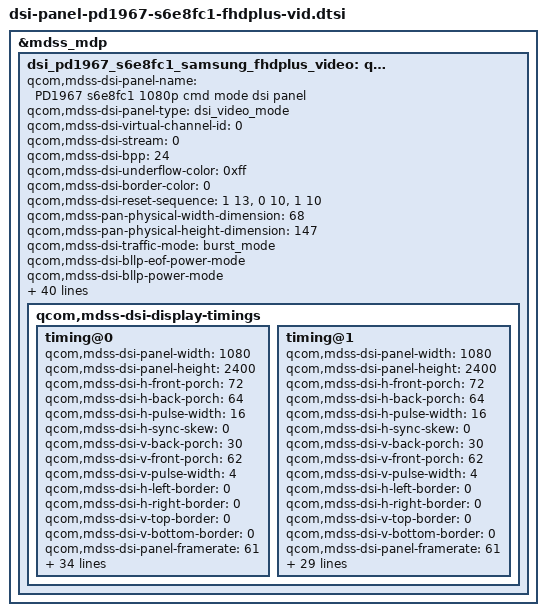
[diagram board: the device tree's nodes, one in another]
/* Copyright (c) 2019, The Linux Foundation. All rights reserved.
 *
 * This program is free software; you can redistribute it and/or modify
 * it under the terms of the GNU General Public License version 2 and
 * only version 2 as published by the Free Software Foundation.
 *
 * This program is distributed in the hope that it will be useful,
 * but WITHOUT ANY WARRANTY; without even the implied warranty of
 * MERCHANTABILITY or FITNESS FOR A PARTICULAR PURPOSE.  See the
 * GNU General Public License for more details.
 */

&mdss_mdp {
	dsi_pd1967_s6e8fc1_samsung_fhdplus_video: qcom,PD1967_mdss_dsi_s6e8fc1_fhdplus_cmd {
		qcom,mdss-dsi-panel-name = "PD1967 s6e8fc1 1080p cmd mode dsi panel";
		qcom,mdss-dsi-panel-type = "dsi_video_mode";
		qcom,mdss-dsi-virtual-channel-id = <0>;
		qcom,mdss-dsi-stream = <0>;
		qcom,mdss-dsi-bpp = <24>;
		qcom,mdss-dsi-underflow-color = <0xff>;
		qcom,mdss-dsi-border-color = <0>;
		qcom,mdss-dsi-reset-sequence = <1 13>, <0 10>, <1 10>;
		qcom,mdss-pan-physical-width-dimension = <68>;
		qcom,mdss-pan-physical-height-dimension = <147>;
		qcom,mdss-dsi-traffic-mode = "burst_mode";//"non_burst_sync_event";
		qcom,mdss-dsi-bllp-eof-power-mode;
		qcom,mdss-dsi-bllp-power-mode;
		qcom,mdss-dsi-lane-0-state;
		qcom,mdss-dsi-lane-1-state;
		qcom,mdss-dsi-lane-2-state;
		qcom,mdss-dsi-lane-3-state;
		qcom,mdss-dsi-dma-trigger = "trigger_sw";
		qcom,mdss-dsi-mdp-trigger = "none";
		qcom,mdss-dsi-lp11-init;
		qcom,mdss-dsi-panel-id = <0x21>;
		qcom,mdss-dsi-project-name = "pd1982";
		qcom,vivo-dsi-panel-type = "oled";
		qcom,dsi-dyn-clk-enable;
		qcom,dsi-dyn-clk-list = <1125476352 1115097984>;
		qcom,mdss-dsi-te-pin-select = <1>;
		qcom,mdss-dsi-wr-mem-start = <0x2c>;
		qcom,mdss-dsi-wr-mem-continue = <0x3c>;
		qcom,mdss-dsi-te-dcs-command = <1>;
		qcom,mdss-dsi-te-check-enable;
		qcom,mdss-dsi-te-using-te-pin;
		qcom,mdss-dsi-panel-mode-switch;

		//qcom,esd-check-enabled;
		qcom,mdss-dsi-panel-status-check-mode = "reg_read";
		qcom,mdss-dsi-panel-status-command = [06 01 00 01 00 00 01 0a];
		qcom,mdss-dsi-panel-status-command-state = "dsi_lp_mode";
		qcom,mdss-dsi-panel-status-value = <0x9F>;
		qcom,mdss-dsi-panel-on-check-value = <0x9F>;
		qcom,mdss-dsi-panel-status-read-length = <1>;
		qcom,mdss-dsi-t-clk-post = <0x0F>;

		qcom,mdss-dsi-t-clk-pre = <0x3A>;

		qcom,panel-supply-entries = <&dsi_panel_pwr_supply_no_labibb>;
		qcom,mdss-dsi-bl-pmic-control-type = "bl_ctrl_dcs";
		qcom,mdss-dsi-bl-min-level = <1>;
		qcom,mdss-dsi-bl-max-level = <2047>;
		qcom,mdss-brightness-max-level = <2047>;
		qcom,platform-en-gpio = <&tlmm 129 0>;
		qcom,platform-te-gpio = <&tlmm 89 0>;
		qcom,platform-reset-gpio = <&tlmm 90 0>;
		

		qcom,mdss-dsi-display-timings {
			timing@0{
				qcom,mdss-dsi-panel-width = <1080>;
				qcom,mdss-dsi-panel-height = <2400>;
				qcom,mdss-dsi-h-front-porch = <72>;
				qcom,mdss-dsi-h-back-porch = <64>;
				qcom,mdss-dsi-h-pulse-width = <16>;
				qcom,mdss-dsi-h-sync-skew = <0>;
				qcom,mdss-dsi-v-back-porch = <30>;
				qcom,mdss-dsi-v-front-porch = <62>;
				qcom,mdss-dsi-v-pulse-width = <4>;
				qcom,mdss-dsi-h-left-border = <0>;
				qcom,mdss-dsi-h-right-border = <0>;
				qcom,mdss-dsi-v-top-border = <0>;
				qcom,mdss-dsi-v-bottom-border = <0>;
				qcom,mdss-dsi-panel-framerate = <61>;
				qcom,mdss-dsi-video-mode;

				qcom,mdss-dsi-panel-phy-timings = 
				[27 21 0A 0B 07 02 04 a0
				 27 21 0A 0B 07 02 04 a0
				 27 21 0A 0B 07 02 04 a0
				 27 21 0A 0B 07 02 04 a0
				 27 22 0A 0B 07 02 04 a0]; /* clk lane */
				qcom,display-topology = <1 0 1>;
				qcom,default-topology-index = <0>;
				
				qcom,mdss-dsi-on-command = [
					/* Sleep Out */
					39 01 00 00 15 00 02 11 00
					39 01 00 00 00 00 02 53 20
					/*39 01 00 00 00 00 03 9F A5 A5
					39 01 00 00 00 00 02 29 00
					39 01 00 00 00 00 03 9F 5A 5A*/
				];

				/* samsung OLED HBM mode */
				qcom,mdss-oled-hbm-on-command-level1 =
				[
					39 00 00 00 00 00 02 53 E0
					39 01 00 00 00 00 03 51 00 8B
				];

				qcom,mdss-oled-hbm-on-command-level2 =
				[
					39 00 00 00 00 00 02 53 E0
					39 01 00 00 00 00 03 51 03 29
				];
					/*fod on sequence
					1.ELVSS DIM OFF & DLY OFF
					2.HBM MODE ON
					3.Wait 1-Frame
					4.PS OFF
					5.image data write
					*/
				qcom,mdss-oled-hbm-on-command-ud-fingerprint =
				[
					/*DLY OFF*/
					39 00 00 00 00 00 03 F0 5A 5A
					39 00 00 00 00 00 03 B0 01 B3
					39 00 00 00 00 00 02 B3 4B
					39 00 00 00 00 00 03 F0 A5 A5
					/*HBM MODE ON*/
					39 00 00 00 00 00 02 53 E0
					39 01 00 00 00 00 03 51 03 29  /*600nit*/
				];
				/* elvss dim on*/
				qcom,mdss-oled-elvss-dim-on-command =
				[
					39 00 00 00 00 00 03 F0 5A 5A
					39 00 00 00 00 00 03 B0 05 B3
					39 00 00 00 00 00 02 B3 87
					39 01 00 00 00 00 03 F0 A5 A5
				];
				/* elvss dim off*/
				qcom,mdss-oled-elvss-dim-off-command =
				[
					39 00 00 00 00 00 03 F0 5A 5A
					39 00 00 00 00 00 03 B0 05 B3
					39 00 00 00 00 00 02 B3 07
					39 01 00 00 00 00 03 F0 A5 A5
				];
					/*fod out sequence:
					1.HBM MODE OFF
					2.PS ON(ignore)
					3.ELVSS DIM ON & DLY ON
					4.image data write
					*/
				qcom,mdss-oled-hbm-off-command-ud-fingerprint =
				[
					/* HBM MODE OFF */
					39 00 00 00 00 00 02 53 20
				];
				/*
				qcom,mdss-oled-dimming-speed =
				[
					39 01 00 00 00 00 03 F0 5A 5A
					39 01 00 00 00 00 02 B0 07
					39 01 00 00 00 00 02 B7 28
					39 01 00 00 00 00 03 F0 A5 A5
					39 01 00 00 00 00 02 53 28
				];

				qcom,mdss-oled-dimming-speed-off =
				[
					39 01 00 00 00 00 02 53 20
				];
				*/

				qcom,mdss-oled-display-on-command =
				[
					39 01 00 00 00 00 02 53 20
					39 01 00 00 00 00 03 9F A5 A5
					39 01 00 00 00 00 02 13 00
					39 01 00 00 00 00 02 29 00
					39 01 00 00 00 00 03 9F 5A 5A
				];

				qcom,video-to-cmd-mode-switch-commands = [
					
				];
				qcom,mdss-oled-aod-on-command =
				[
					/* Sleep Out */
					//39 01 00 00 00 00 03 F0 5A 5A
					//39 01 00 00 00 00 03 FC 5A 5A
					//39 01 00 00 00 00 03 B0 14 FE
					//39 01 00 00 00 00 02 FE 12
					//39 01 00 00 0A 00 02 11 00
					39 01 00 00 00 00 02 F2 03
					39 01 00 00 0A 00 02 35 00
					/*AOD setting */
					//39 01 00 00 00 00 02 81 30
					//39 01 00 00 00 00 03 B0 01 81
					//39 01 00 00 00 00 1F 81 13 C4 1E 83 2C 1A 82 7B C8 80 00 00 00 00 00 00 00 00 00 00 00 00 00 00 00 00 00 00 00 00
					//39 01 00 00 00 00 03 B0 1F 81
					//39 01 00 00 00 00 0E 81 20 30 00 00 00 00 FF 00 00 00 00 00 00
					39 01 00 00 00 00 02 81 30
					39 01 00 00 00 00 03 B0 01 81
					39 01 00 00 00 00 1F 81 11 86 04 27 4B 00 00 00 00 00 00 00 00 00 00 00 00 00 00 00 00 00 00 00 00 00 00 00 00 00
					39 01 00 00 00 00 03 B0 1F 81
					39 01 00 00 00 00 0E 81 00 30 00 00 00 00 FF 00 00 00 00 00 00
					39 01 00 00 00 00 03 Fc 5A 5A
					39 01 00 00 00 00 03 B0 03 C2
					39 01 00 00 00 00 02 C2 04
					39 01 00 00 00 00 03 Fc A5 A5
					39 01 00 00 00 00 02 53 22
					39 01 00 00 00 00 03 B0 14 FE
					39 01 00 00 64 00 02 FE 10
				];
				
				qcom,cmd-to-video-mode-post-switch-commands = [
					/*D-IC MIPI vid mode*/
					39 01 00 00 20 00 02 00 00
					39 01 00 00 00 00 03 F0 5A 5A
					39 01 00 00 00 00 02 F2 0F   /*03:cmd; 0F video*/
					39 01 00 00 00 00 03 F0 A5 A5
					/*AOD AMP Setting off*/
					39 01 00 00 00 00 03 FC 5A 5A
					39 01 00 00 00 00 03 B0 05 FD
					39 01 00 00 00 00 02 FD 6F
					39 01 00 00 00 00 03 FC A5 A5
					/*AOD Mode OFF*/
					39 01 00 00 00 00 02 53 20
					39 01 00 00 00 00 03 9F A5 A5
					39 01 00 00 00 00 02 29 00
					39 01 00 00 00 00 03 9F 5A 5A
				];
				qcom,video-to-cmd-mode-switch-commands-state =
						"dsi_lp_mode";
				qcom,mdss-alpm-command-state = "dsi_lp_mode";
				qcom,mdss-dsi-off-command = [
					39 01 00 00 00 00 03 9F A5 A5
					39 01 00 00 0B 00 02 28 00
					39 01 00 00 96 00 02 10 00
					39 01 00 00 00 00 03 9F 5A 5A
				];
				qcom,mdss-dsi-on-command-state = "dsi_lp_mode";
				qcom,mdss-dsi-off-command-state = "dsi_lp_mode";
				qcom,mdss-dsi-h-sync-pulse = <0>;
			};
			timing@1{
				qcom,mdss-dsi-panel-width = <1080>;
				qcom,mdss-dsi-panel-height = <2400>;
				qcom,mdss-dsi-h-front-porch = <72>;
				qcom,mdss-dsi-h-back-porch = <64>;
				qcom,mdss-dsi-h-pulse-width = <16>;
				qcom,mdss-dsi-h-sync-skew = <0>;
				qcom,mdss-dsi-v-back-porch = <30>;
				qcom,mdss-dsi-v-front-porch = <62>;
				qcom,mdss-dsi-v-pulse-width = <4>;
				qcom,mdss-dsi-h-left-border = <0>;
				qcom,mdss-dsi-h-right-border = <0>;
				qcom,mdss-dsi-v-top-border = <0>;
				qcom,mdss-dsi-v-bottom-border = <0>;
				qcom,mdss-dsi-panel-framerate = <61>;
				qcom,mdss-dsi-panel-jitter = <0x4 0x1>;
				qcom,mdss-dsi-cmd-mode;

				qcom,mdss-dsi-panel-phy-timings = 
				[27 21 0A 0B 07 02 04 a0
				 27 21 0A 0B 07 02 04 a0
				 27 21 0A 0B 07 02 04 a0
				 27 21 0A 0B 07 02 04 a0
				 27 22 0A 0B 07 02 04 a0]; /* clk lane */
				qcom,display-topology = <1 0 1>;
				qcom,default-topology-index = <0>;

				qcom,mdss-dsi-on-command = [
					/* Sleep Out */
					39 01 00 00 00 00 03 F0 5A 5A
					39 01 00 00 00 00 03 FC 5A 5A
					39 01 00 00 00 00 03 B0 14 FE
					39 01 00 00 00 00 02 FE 12
					39 01 00 00 0A 00 02 11 00
					39 01 00 00 00 00 02 F2 03
					39 01 00 00 0A 00 02 35 00
					/*AOD setting */
					//39 01 00 00 00 00 02 81 30
					//39 01 00 00 00 00 03 B0 01 81
					//39 01 00 00 00 00 1F 81 13 C4 1E 83 2C 1A 82 7B C8 80 00 00 00 00 00 00 00 00 00 00 00 00 00 00 00 00 00 00 00 00
					//39 01 00 00 00 00 03 B0 1F 81
					//39 01 00 00 00 00 0E 81 20 30 00 00 00 00 FF 00 00 00 00 00 00
					39 01 00 00 00 00 02 81 30
					39 01 00 00 00 00 03 B0 01 81
					39 01 00 00 00 00 1F 81 11 86 04 27 4B 00 00 00 00 00 00 00 00 00 00 00 00 00 00 00 00 00 00 00 00 00 00 00 00 00
					39 01 00 00 00 00 03 B0 1F 81
					39 01 00 00 00 00 0E 81 00 30 00 00 00 00 FF 00 00 00 00 00 00
					39 01 00 00 00 00 03 Fc 5A 5A
					39 01 00 00 00 00 03 B0 03 C2
					39 01 00 00 00 00 02 C2 04
					39 01 00 00 00 00 03 Fc A5 A5
					39 01 00 00 00 00 02 53 22
					39 01 00 00 00 00 03 B0 14 FE
					39 01 00 00 64 00 02 FE 10
				];

				/* samsung OLED AOD mode, defaut mode  HLPM high brightness */
				qcom,mdss-oled-aod-on-command =
				[
					/*display on*/
					39 01 00 00 00 00 03 9F A5 A5
					39 01 00 00 00 00 02 29 00
					39 01 00 00 00 00 03 9F 5A 5A
					39 01 00 00 00 00 03 F0 A5 A5
					39 01 00 00 00 00 03 FC A5 A5
				];

				qcom,mdss-oled-aod-off-command =
				[
					39 00 00 00 00 00 03 9F A5 A5
					39 00 00 00 00 00 02 28 00
					39 01 00 00 00 00 03 9F 5A 5A
				];

				qcom,cmd-to-video-mode-switch-commands = [
					//39 01 00 00 00 00 03 9F A5 A5
					//39 01 00 00 00 00 02 28 00
					//39 01 00 00 00 00 03 9F 5A 5A
				];
				
				qcom,video-to-cmd-mode-post-switch-commands = [
					/*display on*/
					39 00 00 00 00 00 03 9F A5 A5
					39 00 00 00 00 00 02 29 00
					39 01 00 00 00 00 03 9F 5A 5A
					//39 01 00 00 00 00 03 F0 A5 A5
					//39 01 00 00 00 00 03 FC A5 A5
				];
				qcom,cmd-to-video-mode-switch-commands-state =
						"dsi_lp_mode";
				qcom,cmd-to-video-mode-post-switch-commands-state =
						"dsi_lp_mode";
				qcom,video-to-cmd-mode-post-switch-commands-state =
						"dsi_lp_mode";
				qcom,mdss-alpm-command-state = "dsi_lp_mode";
				qcom,mdss-dsi-off-command = [
					39 01 00 00 00 00 03 9F A5 A5
					39 01 00 00 0B 00 02 28 00
					39 01 00 00 00 00 03 9F 5A 5A
					/*D-IC MIPI vid mode*/
					39 01 00 00 00 00 03 F0 5A 5A
					39 01 00 00 22 00 02 F2 0F   /*03:cmd; 0F video*/
					39 01 00 00 00 00 03 F0 A5 A5
					/*AOD AMP Setting off*/
					39 01 00 00 00 00 03 FC 5A 5A
					39 01 00 00 00 00 03 B0 05 FD
					39 01 00 00 00 00 02 FD 6F
					39 01 00 00 00 00 03 FC A5 A5
					/*AOD Mode OFF*/
					39 01 00 00 00 00 02 53 20
					39 01 00 00 00 00 03 9F A5 A5
					39 01 00 00 96 00 02 10 00
					39 01 00 00 00 00 03 9F 5A 5A
				];
				qcom,mdss-oled-display-on-command =
				[
					/*display off*/
					39 01 00 00 00 00 03 9F A5 A5
					39 01 00 00 23 00 02 28 00
					39 01 00 00 00 00 03 9F 5A 5A
					/*D-IC MIPI vid mode*/
					39 01 00 00 00 00 03 F0 5A 5A
					39 01 00 00 22 00 02 F2 0F   /*03:cmd; 0F video*/
					39 01 00 00 00 00 03 F0 A5 A5
					/*AOD AMP Setting off*/
					39 01 00 00 00 00 03 FC 5A 5A
					39 01 00 00 00 00 03 B0 05 FD
					39 01 00 00 00 00 02 FD 6F
					39 01 00 00 00 00 03 FC A5 A5
					/*AOD Mode OFF*/
					39 01 00 00 00 00 02 53 20
					/*display on*/
					39 01 00 00 00 00 03 9F A5 A5
					39 01 00 00 00 00 02 29 00
					39 01 00 00 00 00 03 9F 5A 5A
				];
				qcom,mdss-dsi-on-command-state = "dsi_lp_mode";
				qcom,mdss-dsi-off-command-state = "dsi_lp_mode";
				qcom,mdss-dsi-h-sync-pulse = <0>;
			};
		};
	};
};
